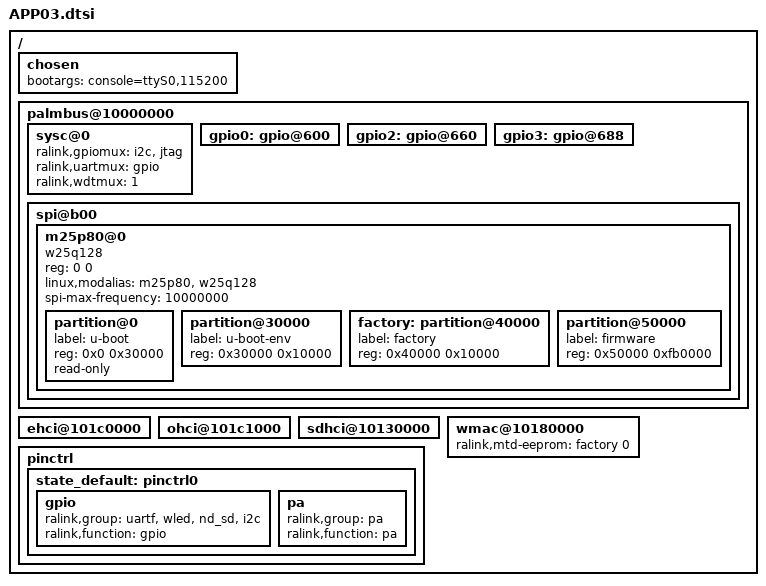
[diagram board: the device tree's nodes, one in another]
/include/ "mt7620a.dtsi"

/ {
	chosen {
		bootargs = "console=ttyS0,115200";
	};
	
	palmbus@10000000 {
		sysc@0 {
			ralink,gpiomux = "i2c", "jtag";
			ralink,uartmux = "gpio";
			ralink,wdtmux = <1>;
		};

		gpio0: gpio@600 {
			status = "okay";
		};

		gpio2: gpio@660 {
			status = "okay";
		};

		gpio3: gpio@688 {
			status = "okay";
		};


		spi@b00 {
			status = "okay";

			m25p80@0 {
				#address-cells = <1>;
				#size-cells = <1>;
				compatible = "w25q128";
				reg = <0 0>;
				linux,modalias = "m25p80", "w25q128";
				spi-max-frequency = <10000000>;

				partition@0 {
					label = "u-boot";
					reg = <0x0 0x30000>;
					read-only;
				};

				partition@30000 {
					label = "u-boot-env";
					reg = <0x30000 0x10000>;
				};

				factory: partition@40000 {
					label = "factory";
					reg = <0x40000 0x10000>;
				};

				partition@50000 {
					label = "firmware";
					reg = <0x50000 0xfb0000>;
				};
			};
		};
	};

	ehci@101c0000 {
		status = "okay";
	};

	ohci@101c1000 {
		status = "okay";
	};

	sdhci@10130000 {
                status = "okay";
        };

	wmac@10180000 {
		ralink,mtd-eeprom = <&factory 0>;
	};

	pinctrl {
		state_default: pinctrl0 {
			gpio {
				ralink,group = "uartf", "wled", "nd_sd", "i2c";
				ralink,function = "gpio";
			};
			pa {
				ralink,group = "pa";
				ralink,function = "pa";
			};
		};
	};
};
